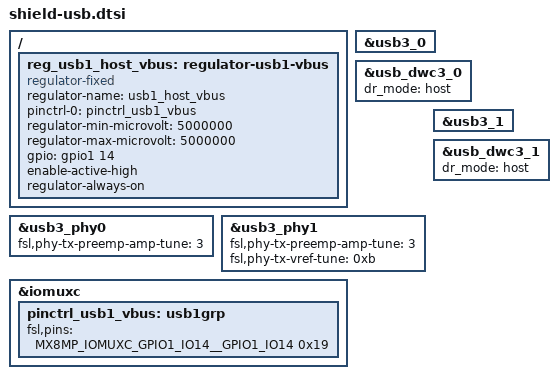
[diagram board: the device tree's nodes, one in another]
// SPDX-License-Identifier: (GPL-2.0+ OR MIT)
/*
 * Copyright 2025 CriticalShift
 */

/ {
	reg_usb1_host_vbus: regulator-usb1-vbus {
		compatible = "regulator-fixed";
		regulator-name = "usb1_host_vbus";
		pinctrl-names = "default";
		pinctrl-0 = <&pinctrl_usb1_vbus>;
		regulator-min-microvolt = <5000000>;
		regulator-max-microvolt = <5000000>;
		gpio = <&gpio1 14 GPIO_ACTIVE_HIGH>;
		enable-active-high;
		regulator-always-on;
	};
};

&usb3_phy0 {
	fsl,phy-tx-preemp-amp-tune = <3>;
	status = "okay";
};

&usb3_0 {
	status = "okay";
};

&usb_dwc3_0 {
	dr_mode = "host";
	status = "okay";
};

&usb3_phy1 {
	fsl,phy-tx-preemp-amp-tune = <3>;
	fsl,phy-tx-vref-tune = <0xb>;
	status = "okay";
};

&usb3_1 {
	status = "okay";
};

&usb_dwc3_1 {
	dr_mode = "host";
	status = "okay";
};

&iomuxc {
	pinctrl_usb1_vbus: usb1grp {
		fsl,pins = <
			MX8MP_IOMUXC_GPIO1_IO14__GPIO1_IO14					0x19
		>;
	};
};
